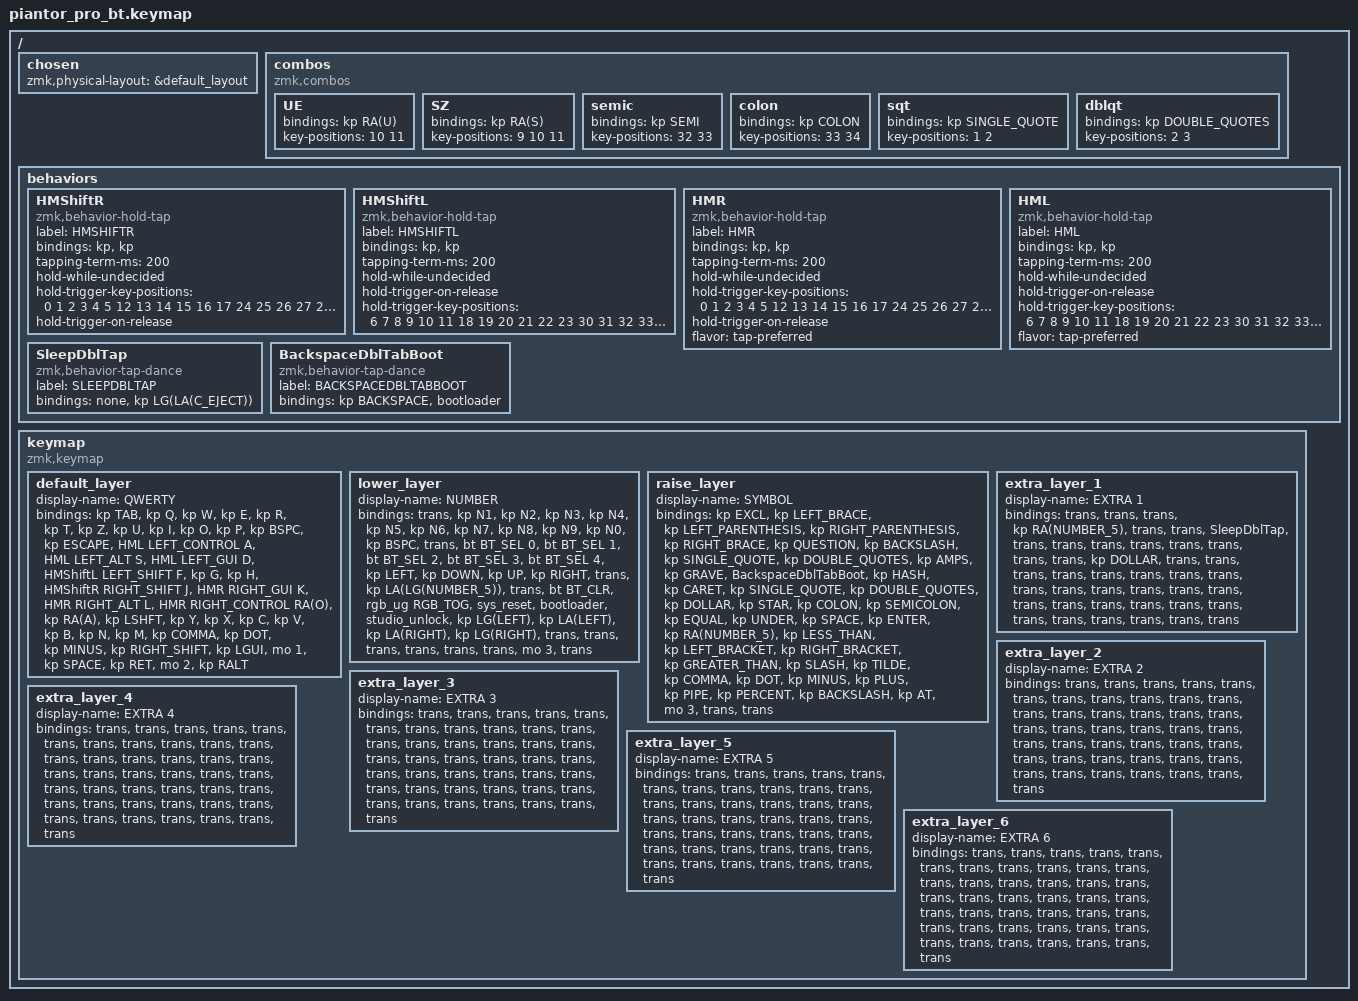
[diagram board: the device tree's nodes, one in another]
/*
 * Copyright (c) 2020 The ZMK Contributors
 *
 * SPDX-License-Identifier: MIT
 */

#include <behaviors.dtsi>
#include <dt-bindings/zmk/bt.h>
#include <dt-bindings/zmk/keys.h>
#include <dt-bindings/zmk/rgb.h>

/ {
    chosen { zmk,physical-layout = &default_layout; };
};

/ {
    combos {
        compatible = "zmk,combos";

        UE {
            bindings = <&kp RA(U)>;
            key-positions = <10 11>;
        };

        SZ {
            bindings = <&kp RA(S)>;
            key-positions = <9 10 11>;
        };

        semic {
            bindings = <&kp SEMI>;
            key-positions = <32 33>;
        };

        colon {
            bindings = <&kp COLON>;
            key-positions = <33 34>;
        };

        sqt {
            bindings = <&kp SINGLE_QUOTE>;
            key-positions = <1 2>;
        };

        dblqt {
            bindings = <&kp DOUBLE_QUOTES>;
            key-positions = <2 3>;
        };
    };

    behaviors {
        HMShiftR: HMShiftR {
            compatible = "zmk,behavior-hold-tap";
            label = "HMSHIFTR";
            bindings = <&kp>, <&kp>;

            #binding-cells = <2>;
            tapping-term-ms = <200>;
            hold-while-undecided;
            hold-trigger-key-positions = <0 1 2 3 4 5 12 13 14 15 16 17 24 25 26 27 28 29 36 37 38>;
            hold-trigger-on-release;
        };

        HMShiftL: HMShiftL {
            compatible = "zmk,behavior-hold-tap";
            label = "HMSHIFTL";
            bindings = <&kp>, <&kp>;

            #binding-cells = <2>;
            tapping-term-ms = <200>;
            hold-while-undecided;
            hold-trigger-on-release;
            hold-trigger-key-positions = <6 7 8 9 10 11 18 19 20 21 22 23 30 31 32 33 34 35 39 40 41>;
        };

        HMR: HMR {
            compatible = "zmk,behavior-hold-tap";
            label = "HMR";
            bindings = <&kp>, <&kp>;

            #binding-cells = <2>;
            tapping-term-ms = <200>;
            hold-while-undecided;
            hold-trigger-key-positions = <0 1 2 3 4 5 12 13 14 15 16 17 24 25 26 27 28 29 36 37 38>;
            hold-trigger-on-release;
            flavor = "tap-preferred";
        };

        HML: HML {
            compatible = "zmk,behavior-hold-tap";
            label = "HML";
            bindings = <&kp>, <&kp>;

            #binding-cells = <2>;
            tapping-term-ms = <200>;
            hold-while-undecided;
            hold-trigger-on-release;
            hold-trigger-key-positions = <6 7 8 9 10 11 18 19 20 21 22 23 30 31 32 33 34 35 39 40 41>;
            flavor = "tap-preferred";
        };

        SleepDblTap: SleepDblTap {
            compatible = "zmk,behavior-tap-dance";
            label = "SLEEPDBLTAP";
            #binding-cells = <0>;
            bindings = <&none>, <&kp LG(LA(C_EJECT))>;
        };

        BackspaceDblTabBoot: BackspaceDblTabBoot {
            compatible = "zmk,behavior-tap-dance";
            label = "BACKSPACEDBLTABBOOT";
            #binding-cells = <0>;
            bindings = <&kp BACKSPACE>, <&bootloader>;
        };
    };

    keymap {
        compatible = "zmk,keymap";

        default_layer {
            display-name = "QWERTY";

            // --------------------------------------------------------------------------------
            // |  TAB |  Q  |  W  |  E  |  R  |  T  |  Y  |  U   |  I  |  O  |  P  | BSPC |
            // | CTRL |  A  |  S  |  D  |  F  |  G  |  H  |  J   |  K  |  L  |  ;  |  '   |
            // | SHFT |  Z  |  X  |  C  |  V  |  B  |  N  |  M   |  ,  |  .  |  /  | ESC  |
            //                    | GUI | LWR | SPC | ENT | RSE  | ALT |

            bindings = <
&kp TAB  &kp Q  &kp W  &kp E  &kp R  &kp T  &kp Z  &kp U  &kp I  &kp O  &kp P  &kp BSPC  &kp ESCAPE  &HML LEFT_CONTROL A  &HML LEFT_ALT S  &HML LEFT_GUI D  &HMShiftL LEFT_SHIFT F  &kp G  &kp H  &HMShiftR RIGHT_SHIFT J  &HMR RIGHT_GUI K  &HMR RIGHT_ALT L  &HMR RIGHT_CONTROL RA(O)  &kp RA(A)  &kp LSHFT  &kp Y  &kp X  &kp C  &kp V  &kp B  &kp N  &kp M  &kp COMMA  &kp DOT  &kp MINUS  &kp RIGHT_SHIFT  &kp LGUI  &mo 1  &kp SPACE  &kp RET  &mo 2  &kp RALT
            >;
        };

        lower_layer {
            display-name = "NUMBER";

            // -----------------------------------------------------------------------------------------
            // |  TAB |  1  |  2  |  3  |  4  |  5    |  6  |  7  |  8  |  9  |  0  | BSPC |
            // | CTRL | BT1 | BT2 | BT3 | BT4 | BT5   | LFT | DWN |  UP | RGT |     |      |
            // | SHFT | BTCR| RGB | RST | BOOT| Unlock|     |     |     |     |     |      |
            //                    | GUI |     | SPC   | ENT |     | ALT |

            bindings = <
&trans  &kp N1  &kp N2  &kp N3  &kp N4  &kp N5  &kp N6  &kp N7  &kp N8  &kp N9  &kp N0  &kp BSPC  &trans  &bt BT_SEL 0  &bt BT_SEL 1  &bt BT_SEL 2  &bt BT_SEL 3  &bt BT_SEL 4  &kp LEFT  &kp DOWN  &kp UP  &kp RIGHT  &trans  &kp LA(LG(NUMBER_5))  &trans  &bt BT_CLR  &rgb_ug RGB_TOG  &sys_reset  &bootloader  &studio_unlock  &kp LG(LEFT)  &kp LA(LEFT)  &kp LA(RIGHT)  &kp LG(RIGHT)  &trans  &trans  &trans  &trans  &trans  &trans  &mo 3  &trans
            >;
        };

        raise_layer {
            display-name = "SYMBOL";

            // -----------------------------------------------------------------------------------------
            // |  TAB |  !  |  @  |  #  |  $  |  %  |  ^  |  &  |  *  |  (  |  )  | BSPC |
            // | CTRL |     |     |     |     |     |  -  |  =  |  [  |  ]  |  \  |  `   |
            // | SHFT |     |     |     |     |     |  _  |  +  |  {  |  }  | "|" |  ~   |
            //                    | GUI |     | SPC | ENT |     | ALT |

            bindings = <
&kp EXCL  &kp LEFT_BRACE  &kp LEFT_PARENTHESIS  &kp RIGHT_PARENTHESIS  &kp RIGHT_BRACE  &kp QUESTION  &kp BACKSLASH  &kp SINGLE_QUOTE  &kp DOUBLE_QUOTES  &kp AMPS  &kp GRAVE  &BackspaceDblTabBoot  &kp HASH  &kp CARET  &kp SINGLE_QUOTE  &kp DOUBLE_QUOTES  &kp DOLLAR  &kp STAR  &kp COLON  &kp SEMICOLON  &kp EQUAL  &kp UNDER  &kp SPACE  &kp ENTER  &kp RA(NUMBER_5)  &kp LESS_THAN  &kp LEFT_BRACKET  &kp RIGHT_BRACKET  &kp GREATER_THAN  &kp SLASH  &kp TILDE  &kp COMMA  &kp DOT  &kp MINUS  &kp PLUS  &kp PIPE  &kp PERCENT  &kp BACKSLASH  &kp AT  &mo 3  &trans  &trans
            >;
        };

        extra_layer_1 {
            display-name = "EXTRA 1";
            bindings = <
&trans  &trans  &trans  &kp RA(NUMBER_5)  &trans  &trans  &SleepDblTap  &trans  &trans  &trans  &trans  &trans  &trans  &trans  &trans  &kp DOLLAR  &trans  &trans  &trans  &trans  &trans  &trans  &trans  &trans  &trans  &trans  &trans  &trans  &trans  &trans  &trans  &trans  &trans  &trans  &trans  &trans  &trans  &trans  &trans  &trans  &trans  &trans
            >;
        };

        extra_layer_2 {
            display-name = "EXTRA 2";
            bindings = <
&trans  &trans  &trans  &trans  &trans  &trans  &trans  &trans  &trans  &trans  &trans  &trans  &trans  &trans  &trans  &trans  &trans  &trans  &trans  &trans  &trans  &trans  &trans  &trans  &trans  &trans  &trans  &trans  &trans  &trans  &trans  &trans  &trans  &trans  &trans  &trans  &trans  &trans  &trans  &trans  &trans  &trans
            >;
        };

        extra_layer_3 {
            display-name = "EXTRA 3";
            bindings = <
&trans  &trans  &trans  &trans  &trans  &trans  &trans  &trans  &trans  &trans  &trans  &trans  &trans  &trans  &trans  &trans  &trans  &trans  &trans  &trans  &trans  &trans  &trans  &trans  &trans  &trans  &trans  &trans  &trans  &trans  &trans  &trans  &trans  &trans  &trans  &trans  &trans  &trans  &trans  &trans  &trans  &trans
            >;
        };

        extra_layer_4 {
            display-name = "EXTRA 4";
            bindings = <
&trans  &trans  &trans  &trans  &trans  &trans  &trans  &trans  &trans  &trans  &trans  &trans  &trans  &trans  &trans  &trans  &trans  &trans  &trans  &trans  &trans  &trans  &trans  &trans  &trans  &trans  &trans  &trans  &trans  &trans  &trans  &trans  &trans  &trans  &trans  &trans  &trans  &trans  &trans  &trans  &trans  &trans
            >;
        };

        extra_layer_5 {
            display-name = "EXTRA 5";
            bindings = <
&trans  &trans  &trans  &trans  &trans  &trans  &trans  &trans  &trans  &trans  &trans  &trans  &trans  &trans  &trans  &trans  &trans  &trans  &trans  &trans  &trans  &trans  &trans  &trans  &trans  &trans  &trans  &trans  &trans  &trans  &trans  &trans  &trans  &trans  &trans  &trans  &trans  &trans  &trans  &trans  &trans  &trans
            >;
        };

        extra_layer_6 {
            display-name = "EXTRA 6";
            bindings = <
&trans  &trans  &trans  &trans  &trans  &trans  &trans  &trans  &trans  &trans  &trans  &trans  &trans  &trans  &trans  &trans  &trans  &trans  &trans  &trans  &trans  &trans  &trans  &trans  &trans  &trans  &trans  &trans  &trans  &trans  &trans  &trans  &trans  &trans  &trans  &trans  &trans  &trans  &trans  &trans  &trans  &trans
            >;
        };
    };
};
